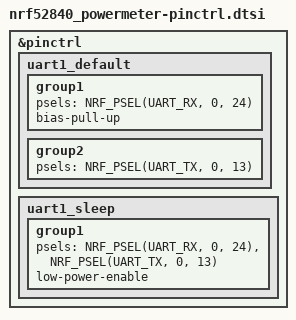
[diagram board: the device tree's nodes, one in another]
/*
 * SPDX-License-Identifier: Apache-2.0
 */

&pinctrl {
	uart1_default: uart1_default {
		group1 {
			psels = <NRF_PSEL(UART_RX, 0, 24)>;
			bias-pull-up;
		};
		group2 {
			psels = <NRF_PSEL(UART_TX, 0, 13)>;
		};
	};

	uart1_sleep: uart1_sleep {
		group1 {
			psels = <NRF_PSEL(UART_RX, 0, 24)>,
				<NRF_PSEL(UART_TX, 0, 13)>;
			low-power-enable;
		};
	};
};
